# PIC32CX0525SG12144 register map
Vendor: Microchip Technology; Series: 0525SG12; File version: 0
CPU: CM4 r1p0, little endian, no MPU, no FPU, 3 interrupt priority bits, 172 interrupts
Registers are 32-bit, read-write, reset 0x0 unless marked. A register's access mark holds for its fields unless they carry their own. Offsets are from the block's base; [hi:lo] are bit positions; {n}, {i} and the like mark numbered series.

## PWM0 — The PWM block generates an arbitrary duty cycle output at frequencies from less than 0.1 Hz to 24 MHz
Base 0x40005800; register names take the prefix PWM_
Same registers: PWM{n} {0x40005800+0x10*n} (n=1..8)
0x00 CNT_ON — This field determines both the frequency and duty cycle of the PWM signal. Setting this field to a value of n will cause the On time of the PWM to be n+1 cycles of the PWM Clock Source. When this field is set to zero and the PWMX_COUNTER_OFF_TIME is not set to zero, the PWM_OUTPUT is held low (Full Off).
0x04 CNT_OFF reset 0xFFFF — This field determine both the frequency and duty cycle of the PWM signal. Setting this field to a value of n will cause the Off time of the PWM to be n+1 cycles of the PWM Clock Source. When this field is set to zero, the PWM_OUTPUT is held high (Full On).
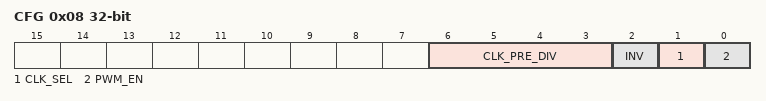
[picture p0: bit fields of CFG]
0x08 CFG — PWMx CONFIGURATION REGISTER
  [6:3] CLK_PRE_DIV — The Clock source for the 16-bit down counter (see PWMx Counter ON Time Register and PWMx Counter OFF Time Register) is determined by bit D1 of this register. The Clock source is then divided by the value of Pre-Divider+1 and the resulting signal determines the rate at which the down counter will be decremented. For example, a Pre-Divider value of 1 divides the input clock by 2 and a value of 2 divides the input clock by 3. A Pre-Divider of 0 will disable the Pre-Divider option.
  [2] INV — 1= PWM_OUTPUT ON State is active low; 0=PWM_OUTPUT ON State is active high.
  [1] CLK_SEL — This bit determines the clock source used by the PWM duty cycle and frequency control logic. 1=CLOCK_LOW. 0=CLOCK_HIGH
  [0] PWM_EN — When the PWM_ENABLE is set to 0 the internal counters are reset and the internal state machine is set to the OFF state. In addition, the PWM_OUTPUT signal is set to the inactive state as determined by the Invert bit. The PWMx Counter ON Time Register and PWMx Counter OFF Time Register are not affected by the PWM_ENABLE bit and may be read and written while the PWM enable bit is 0. 1=Enabled (default); 0=Disabled (gates clocks to save power).

## PECI — The PECI Interface allows the EC to retrieve temperature readings from PECI-compliant devices.
Base 0x40006400
0x00 WDATA 8-bit — The Write Data Register provides access to a 32-byte Transmit FIFO.
0x04 RDATA 8-bit — The Read Data Register provides access to a 32-byte Receive FIFO.
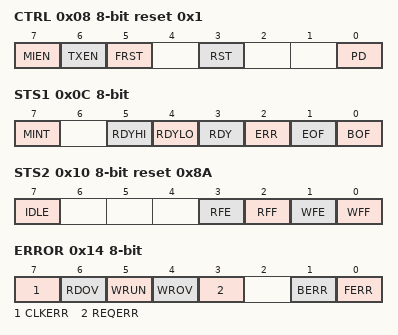
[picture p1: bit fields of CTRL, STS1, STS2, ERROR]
0x08 CTRL 8-bit reset 0x1 — Control Register
  [7] MIEN — MIEN is the Master Interrupt Enable
  [6] TXEN — TXEN is the Transmit Enable bit.
  [5] FRST — FRST is the FIFO Reset bit.
  [3] RST — RST indicates that the PECI Core should be reset.
  [0] PD — PD (Power Down) along with RST controls the Power Management Interface
0x0C STS1 8-bit — Status Register 1
  [7] MINT — MINT is the Master Interrupt Status bit and is asserted when any interrupt status bit in the Interrupt Interface is asserted.
  [5] RDYHI — RDYHI is asserted '1' on the rising edge of the READY signal function (R/WC)
  [4] RDYLO — RDYLO is asserted '1' on the falling edge of the READY signal function (R/WC)
  [3] RDY — RDY represents the state of the READY signal function
  [2] ERR — ERR Indicates that an error for the current transaction has been detected.
  [1] EOF — EOF (End of Frame) is asserted following Message Stop (tSTOP). (R/WC)
  [0] BOF — BOF (Beginning of Frame) is asserted when the PECI Core begins Address Timing Negotiation. (R/WC)
0x10 STS2 8-bit ro reset 0x8A — Status Register 2
  [7] IDLE — The IDLE status bit indicates when the SST/PECI bus is idle and a new transaction may begin.
  [3] RFE — RFE indicates that the Read Data Register FIFO is empty. RFE does not generate an interrupt.
  [2] RFF — RFF indicates that the Read Data Register FIFO is full.
  [1] WFE — WFE indicates that the Write Data Register FIFO is empty.
  [0] WFF — WFF indicates that the Write Data Register FIFO is full. WFF does not generate an interrupt.
0x14 ERROR 8-bit
  [7] CLKERR — CLKERR indicates that the READY signal function in the Hardware Interface was de-asserted in the middle of a transaction (R/WC)
  [6] RDOV — RDOV (Read Overrun). RDOV indicates that the internal read buffer has overflowed (R/WC)
  [5] WRUN — WRUN (Write Underrun). (R/WC)
  [4] WROV — WROV (Write Overrun). (R/WC)
  [3] REQERR — REQERR is asserted if PEC_AVAILABLE (READY) input is not asserted when the counts down to zero as shown in. When asserted, REQERR can generate interrupt. (R/WC)
  [1] BERR — BERR (Bus Error). Bus contention has been detected. BERR is asserted when the PECI Module reads a value that is different from what it has driven (R/WC)
  [0] FERR — FERR (Frame Check Sequence Error). (R/WC)
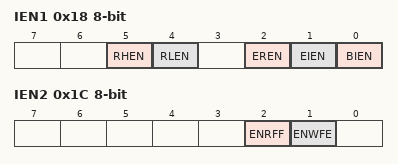
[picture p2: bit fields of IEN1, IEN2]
0x18 IEN1 8-bit — Interrupt Enable 1 Register
  [5] RHEN — When the RHEN bit is asserted '1' the RDYHI interrupt is enabled.
  [4] RLEN — When the RLEN bit is asserted '1' the RDYLO interrupt is enabled.
  [2] EREN — When the EREN bit is asserted '1' the ERR interrupt is enabled.
  [1] EIEN — When the EIEN bit is asserted '1' the EOF interrupt is enabled.
  [0] BIEN — When the BIEN bit is asserted '1' the BOF interrupt is enabled.
0x1C IEN2 8-bit — Interrupt Enable 2 Register
  [2] ENRFF — When the ENRFF bit is asserted '1' the RFF interrupt is enabled.
  [1] ENWFE — When the ENWFE bit is asserted '1' the WFE interrupt is enabled.
0x20 OPTBTLO 8-bit reset 0x16 — Optimal Bit Time Register (Low Byte)
0x24 OPTBTHI 8-bit — Optimal Bit Time Register (High Byte)
0x30 BDCTRL reset 0x6 — Baud Control Register. The baud div value divides down the sytem clock frequency to create the peci CORE_CLK frequency.
0x40 BLKID reset 0xC0 — Block ID Register
0x44 BLKREV — Revision Register
